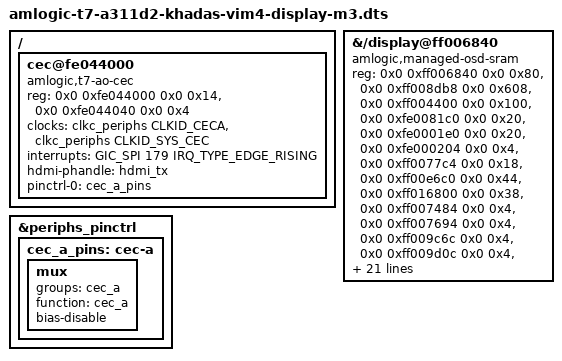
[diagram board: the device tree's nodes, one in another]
// SPDX-License-Identifier: (GPL-2.0+ OR MIT)
/* Experimental display extension; the deployed default remains unchanged. */
#include "amlogic-t7-a311d2-khadas-vim4-display-m2.dts"

&{/display@ff006840} {
	amlogic,managed-osd-sram;
	reg = <0x0 0xff006840 0x0 0x80>,
	      <0x0 0xff008db8 0x0 0x608>,
	      <0x0 0xff004400 0x0 0x100>,
	      <0x0 0xfe0081c0 0x0 0x20>,
	      <0x0 0xfe0001e0 0x0 0x20>,
	      <0x0 0xfe000204 0x0 0x4>,
	      <0x0 0xff0077c4 0x0 0x18>,
	      <0x0 0xff00e6c0 0x0 0x44>,
	      <0x0 0xff016800 0x0 0x38>,
	      <0x0 0xff007484 0x0 0x4>,
	      <0x0 0xff007694 0x0 0x4>,
	      <0x0 0xff009c6c 0x0 0x4>,
	      <0x0 0xff009d0c 0x0 0x4>,
	      <0x0 0xff00e440 0x0 0x38>,
	      <0x0 0xff0068c0 0x0 0x80>,
	      <0x0 0xff00f600 0x0 0x80>,
	      <0x0 0xff016900 0x0 0x38>,
	      <0x0 0xff016a00 0x0 0x38>,
	      <0x0 0xff006834 0x0 0x8>,
	      <0x0 0xff006990 0x0 0xc>,
	      <0x0 0xff006af4 0x0 0x4>,
	      <0x0 0xff006b7c 0x0 0x4>,
	      <0x0 0xff006b3c 0x0 0x4>,
	      <0x0 0xff00f680 0x0 0x4>;
	reg-names = "osd1", "venc", "rdma", "pll", "vid2", "vid-div",
		    "vpp", "blend", "scaler", "post-size", "out-size", "hdmi-setting",
		    "hdmi-format", "osd-matrix",
		    "osd2", "osd3", "scaler2", "scaler3", "osd-paths",
		    "osd2-address", "osd2-unpack", "dimm1", "dimm2", "dimm3";
	power-domains = <&pwrc PWRC_T7_VPU_HDMI_ID>,
			<&pwrc PWRC_T7_VI_CLK1_ID>, <&pwrc PWRC_T7_VI_CLK2_ID>,
			<&pwrc PWRC_T7_OSD1_MEM_ID>, <&pwrc PWRC_T7_OSD2_MEM_ID>,
			<&pwrc PWRC_T7_OSD3_MEM_ID>, <&pwrc PWRC_T7_OSD_SCALE_MEM_ID>,
			<&pwrc PWRC_T7_OSD2_SCALE_MEM_ID>, <&pwrc PWRC_T7_OSD_BLD34_MEM_ID>,
			<&pwrc PWRC_T7_RDMA_MEM_ID>;
};

/ {
	cec@fe044000 {
		compatible = "amlogic,t7-ao-cec";
		reg = <0x0 0xfe044000 0x0 0x14>, <0x0 0xfe044040 0x0 0x4>;
		reg-names = "core", "cecb-route";
		clocks = <&clkc_periphs CLKID_CECA>, <&clkc_periphs CLKID_SYS_CEC>;
		clock-names = "core", "pclk";
		interrupts = <GIC_SPI 179 IRQ_TYPE_EDGE_RISING>;
		hdmi-phandle = <&hdmi_tx>;
		pinctrl-names = "default";
		pinctrl-0 = <&cec_a_pins>;
	};
};

&periphs_pinctrl {
	cec_a_pins: cec-a {
		mux {
			groups = "cec_a";
			function = "cec_a";
			bias-disable;
		};
	};
};
